# APM32M35XX register map
File version: 1.0
Registers are 32-bit, read-write, reset 0x0 unless marked. A register's access mark holds for its fields unless they carry their own. Offsets are from the block's base; [hi:lo] are bit positions; {n}, {i} and the like mark numbered series; 'fields as' and 'values as' point back to an identical list.

## DMA — DMA controller
Base 0x40020000
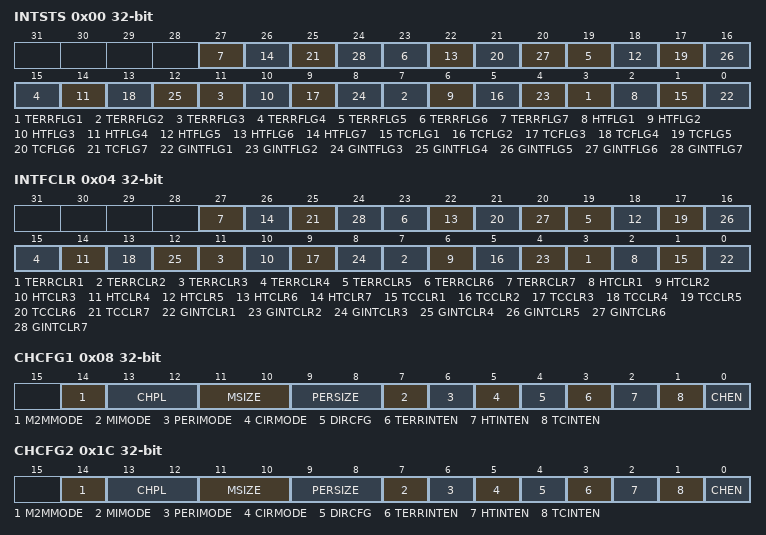
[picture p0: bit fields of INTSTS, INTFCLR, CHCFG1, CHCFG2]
0x00 INTSTS ro — DMA interrupt status register
  [4n-1] TERRFLG{n} (n=1..7) — Channel {n} Transfer Error flag
  [4n-2] HTFLG{n} (n=1..7) — Channel {n} Half Transfer Complete flag
  [4n-3] TCFLG{n} (n=1..7) — Channel {n} Transfer Complete flag
  [4n-4] GINTFLG{n} (n=1..7) — Channel {n} All interrupt flag
0x04 INTFCLR wo — DMA interrupt flag clear register
  [4n-1] TERRCLR{n} (n=1..7) — Channel {n} Transfer Error clear
  [4n-2] HTCLR{n} (n=1..7) — Channel {n} Half Transfer clear
  [4n-3] TCCLR{n} (n=1..7) — Channel {n} Transfer Complete clear
  [4n-4] GINTCLR{n} (n=1..7) — Channel {n} All interrupt clear
0x08 CHCFG1 — DMA channel 1 configuration register
  [14] M2MMODE — Memory to memory mode
  [13:12] CHPL — Channel Priority level
  [11:10] MSIZE — Memory size
  [9:8] PERSIZE — Peripheral size
  [7] MIMODE — Memory increment mode
  [6] PERIMODE — Peripheral increment mode
  [5] CIRMODE — Circular mode
  [4] DIRCFG — Data transfer direction
  [3] TERRINTEN — Transfer error interrupt enable
  [2] HTINTEN — Half Transfer interrupt enable
  [1] TCINTEN — Transfer complete interrupt enable
  [0] CHEN — Channel enable
0x0C CHNDATA1 — DMA channel 1 number of data register
  [15:0] NDATAT — Number of data to transfer
0x10 CHPADDR1 — DMA channel 1 peripheral address register
  [31:0] PERADDR — Peripheral address
{0x0+0x14*i} CHMADDR{i} (i=1..7) — DMA channel {i} memory address register
  [31:0] MEMADDR — Memory address
0x1C CHCFG2 — DMA channel 2 configuration register
  fields as CHCFG1
0x20 CHNDATA2 — DMA channel 2 number of data register
  [15:0] NDATAT — Number of data to transfer
0x24 CHPADDR2 — DMA channel 2 peripheral address register
  [31:0] PERADDR — Peripheral address
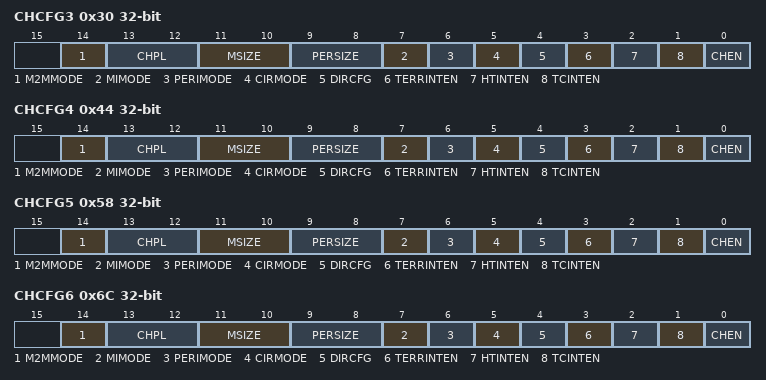
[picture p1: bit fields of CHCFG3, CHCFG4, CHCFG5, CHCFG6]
0x30 CHCFG3 — DMA channel 3 configuration register
  fields as CHCFG1
0x34 CHNDATA3 — DMA channel 3 number of data register
  [15:0] NDATAT — Number of data to transfer
0x38 CHPADDR3 — DMA channel 3 peripheral address register
  [31:0] PERADDR — Peripheral address
0x44 CHCFG4 — DMA channel 4 configuration register
  fields as CHCFG1
0x48 CHNDATA4 — DMA channel 4 number of data register
  [15:0] NDATAT — Number of data to transfer
0x4C CHPADDR4 — DMA channel 4 peripheral address register
  [31:0] PERADDR — Peripheral address
0x58 CHCFG5 — DMA channel 5 configuration register
  fields as CHCFG1
0x5C CHNDATA5 — DMA channel 5 number of data register
  [15:0] NDATAT — Number of data to transfer
0x60 CHPADDR5 — DMA channel 5 peripheral address register
  [31:0] PERADDR — Peripheral address
0x6C CHCFG6 — DMA channel 6 configuration register
  fields as CHCFG1
0x70 CHNDATA6 — DMA channel 6 number of data register
  [15:0] NDATAT — Number of data to transfer
0x74 CHPADDR6 — DMA channel 6 peripheral address register
  [31:0] PERADDR — Peripheral address
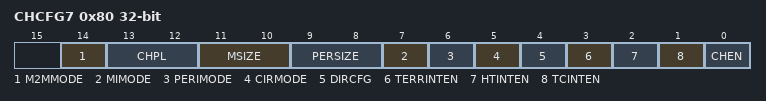
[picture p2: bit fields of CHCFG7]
0x80 CHCFG7 — DMA channel 7 configuration register
  fields as CHCFG1
0x84 CHNDATA7 — DMA channel 7 number of data register
  [15:0] NDATAT — Number of data to transfer
0x88 CHPADDR7 — DMA channel 7 peripheral address register
  [31:0] PERADDR — Peripheral address

## SYSCFG — System configuration controller
Base 0x40010000
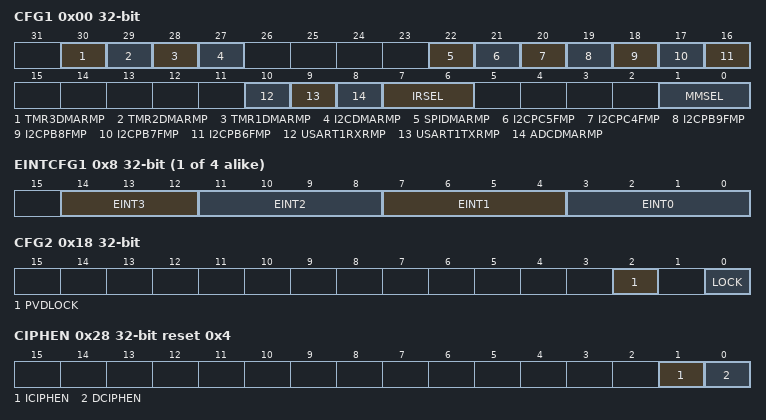
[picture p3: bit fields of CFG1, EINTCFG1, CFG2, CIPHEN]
0x00 CFG1 — configuration register 1
  [30] TMR3DMARMP — TMR3 DMA Request Remap
  [29] TMR2DMARMP — TMR2 DMA Request Remap
  [28] TMR1DMARMP — TMR1 DMA Request Remap
  [27] I2CDMARMP — I2C DMA Request Remap
  [22] SPIDMARMP — SPI DMA Request Remap
  [21] I2CPC5FMP — FM+ driving capability activation for PC5
  [20] I2CPC4FMP — FM+ driving capability activation for PC4
  [19] I2CPB9FMP — Fast Mode Plus (FM+) driving capability activation bits.
  [18] I2CPB8FMP — Fast Mode Plus (FM+) driving capability activation bits.
  [17] I2CPB7FMP — Fast Mode Plus (FM+) driving capability activation bits.
  [16] I2CPB6FMP — Fast Mode Plus (FM plus) driving capability activation bits.
  [10] USART1RXRMP — USART1 RX DMA Request Remap
  [9] USART1TXRMP — USART1 TX DMA Request Remap
  [8] ADCDMARMP — ADC DMA Request Remap
  [7:6] IRSEL — IR Modulation Envelope Signal Select
  [1:0] MMSEL — Memory mapping selection bits
{0x4+4i} EINTCFG{i} (i=1..4) — external interrupt configuration register {i}
  [14:12] EINT{4i-1} — EINT {4i-1} configuration bits
  [11:8] EINT{4i-2} — EINT {4i-2} configuration bits
  [7:4] EINT{4i-3} — EINT {4i-3} configuration bits
  [3:0] EINT{4i-4} — EINT {4i-4} configuration bits
0x18 CFG2 — configuration register 2
  [2] PVDLOCK — PVD lock enable bit
  [0] LOCK — Cortex-M0 Hardfault enable bit
0x20 DCODE wo — data code cipher key register
  [31:0] DKEY — Data Code Cipher Key
0x24 ICODE wo — instruction cipher key register
  [31:0] IKEY — Instruction Code Cipher Key
0x28 CIPHEN reset 0x4 — cipher enable register
  [1] ICIPHEN — Instruction Code Cipher Enable
  [0] DCIPHEN — Data Code Cipher Enable
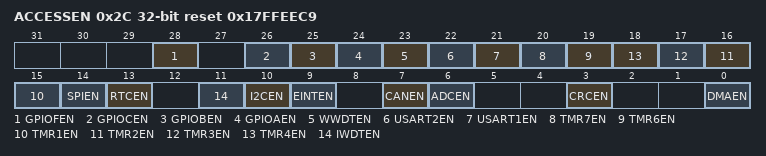
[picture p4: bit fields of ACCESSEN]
0x2C ACCESSEN reset 0x17FFEEC9 — cpu and dma access enable register
  [28] GPIOFEN — CPU and DMA Access GPIOF Enable
  [26] GPIOCEN — CPU and DMA Access GPIOC Enable
  [25] GPIOBEN — CPU and DMA Access GPIOB Enable
  [24] GPIOAEN — CPU and DMA Access GPIOA Enable
  [23] WWDTEN — CPU and DMA Access WWDT Enable
  [22] USART2EN — CPU and DMA Access USART2 Enable
  [21] USART1EN — CPU and DMA Access USART1 Enable
  [20] TMR7EN — CPU and DMA Access TMR7 Enable
  [19] TMR6EN — CPU and DMA Access TMR6 Enable
  [n+14] TMR{n}EN (n=1..4) — CPU and DMA Access TMR{n} Enable
  [14] SPIEN — CPU and DMA Access SPI Enable
  [13] RTCEN — CPU and DMA Access RTC Enable
  [11] IWDTEN — CPU and DMA Access IWDT Enable
  [10] I2CEN — CPU and DMA Access I2C Enable
  [9] EINTEN — CPU and DMA Access EINT Enable
  [7] CANEN — CPU and DMA Access CAN Enable
  [6] ADCEN — CPU and DMA Access ADC Enable
  [3] CRCEN — CPU and DMA Access CRC Enable
  [0] DMAEN — CPU Access DMA Enable
